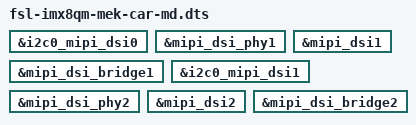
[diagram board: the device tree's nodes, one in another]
/*
 * Copyright 2019 NXP
 *
 * This program is free software; you can redistribute it and/or
 * modify it under the terms of the GNU General Public License
 * as published by the Free Software Foundation; either version 2
 * of the License, or (at your option) any later version.
 *
 * This program is distributed in the hope that it will be useful,
 * but WITHOUT ANY WARRANTY; without even the implied warranty of
 * MERCHANTABILITY or FITNESS FOR A PARTICULAR PURPOSE.  See the
 * GNU General Public License for more details.
 */

#include "fsl-imx8qm-mek-car.dts"

&i2c0_mipi_dsi0 {
       status = "okay";
};

&mipi_dsi_phy1 {
       status = "okay";
};

&mipi_dsi1 {
       status = "okay";
};

&mipi_dsi_bridge1 {
       status = "okay";
};

&i2c0_mipi_dsi1 {
       status = "okay";
};

&mipi_dsi_phy2 {
   status = "okay";
};

&mipi_dsi2 {
   status = "okay";
};

&mipi_dsi_bridge2 {
   status = "okay";
};
